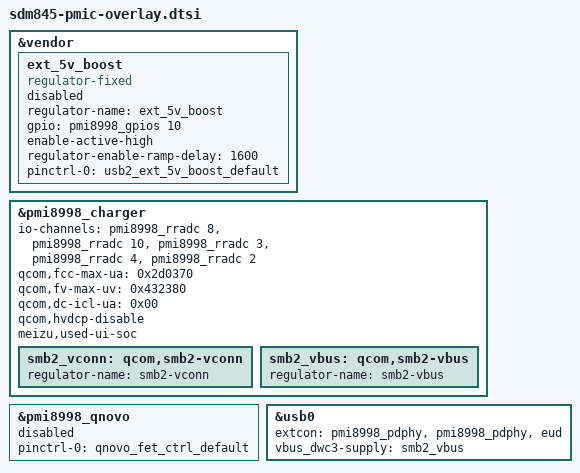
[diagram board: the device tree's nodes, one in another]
/* Copyright (c) 2017-2018, The Linux Foundation. All rights reserved.
 *
 * This program is free software; you can redistribute it and/or modify
 * it under the terms of the GNU General Public License version 2 and
 * only version 2 as published by the Free Software Foundation.
 *
 * This program is distributed in the hope that it will be useful,
 * but WITHOUT ANY WARRANTY; without even the implied warranty of
 * MERCHANTABILITY or FITNESS FOR A PARTICULAR PURPOSE.  See the
 * GNU General Public License for more details.
 */

#include <dt-bindings/gpio/gpio.h>

#include "pmi8998.dtsi"

&vendor {
	ext_5v_boost: ext_5v_boost {
		status = "disabled";
		compatible = "regulator-fixed";
		regulator-name = "ext_5v_boost";
		gpio = <&pmi8998_gpios 10 GPIO_ACTIVE_HIGH>;
		enable-active-high;

		regulator-enable-ramp-delay = <1600>;
		pinctrl-names = "default";
		pinctrl-0 = <&usb2_ext_5v_boost_default>;
	};
};

&pmi8998_charger {
	io-channels = 
		<&pmi8998_rradc 8>,
		<&pmi8998_rradc 10>,
		<&pmi8998_rradc 3>,
		<&pmi8998_rradc 4>,
		<&pmi8998_rradc 2>;
	io-channel-names = 
		"charger_temp", 
		"charger_temp_max", 
		"usbin_i", 
		"usbin_v", 
		"skin_temp";
	
	status = "ok";
	qcom,fcc-max-ua = <0x2d0370>;
	qcom,fv-max-uv = <0x432380>;
	qcom,dc-icl-ua = <0x00>;
	qcom,hvdcp-disable;
	meizu,used-ui-soc;

	smb2_vconn: qcom,smb2-vconn {
		regulator-name = "smb2-vconn";
	};
	smb2_vbus: qcom,smb2-vbus {
		regulator-name = "smb2-vbus";
	};
};

&pmi8998_qnovo {
	pinctrl-names = "default";
	pinctrl-0 = <&qnovo_fet_ctrl_default>;
	status = "disabled";
};

&usb0 {
	extcon = <&pmi8998_pdphy>, <&pmi8998_pdphy>, <&eud>;
	vbus_dwc3-supply = <&smb2_vbus>;
};
